# DSS_RCM register map
Vendor: Texas Instruments
Peripheral module from a debugger description file (folder awr2544).
Registers are 32-bit, read-write, no defined reset value unless marked. A register's access mark holds for its fields unless they carry their own. Offsets are as the file gives them; lines under a group give offsets from that group; [hi:lo] are bit positions; {n}, {i} and the like mark numbered series; 'fields as' and 'values as' point back to an identical list; <NAME> marks a mode.

## DSS_RCM
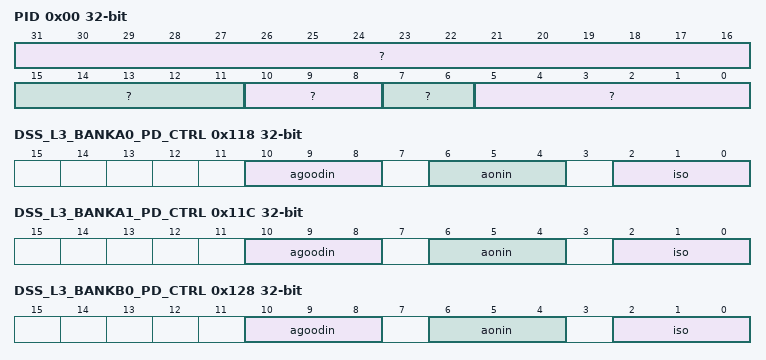
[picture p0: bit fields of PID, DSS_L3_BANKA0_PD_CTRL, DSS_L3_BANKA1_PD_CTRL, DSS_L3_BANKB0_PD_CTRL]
0x00 PID ro
  [31:16] ?, [15:11] ?, [10:8] ?, [7:6] ?, [5:0] ?
0x04 HW_REG0
  [31:0] hwreg — HW Reserved regiser
0x08 HW_REG1
  [31:0] hwreg — HW Reserved regiser
0x0C PREVIOUS_NAME
  [31:0] hwreg — HW Reserved regiser
0x10 HW_REG3
  [31:0] hwreg — HW Reserved regiser
0x90 DSS_HWA_CLK_SRC_SEL
  [2:0] clksrcsel — Select line for selecting source clock for DSS HWA. Data should be loaded as multibit. Write 3'b000 : TOPRCM_CR5_CLK Write 3'b111 : TOPRCM_SYS_CLK
0xBC DSS_HWA_CLK_GATE
  [2:0] gated — Clock gatring config for DSS HWA Data should be loaded as multibit. Write 3'b000 : Clock is ungated Write 3'b111 : Clock is gated
0xD0 DSS_CBUFF_CLK_GATE
  [2:0] gated — Clock gating config for DSS CBUFF Data should be loaded as multibit. Write 3'b000 : Clock is ungated Write 3'b111 : Clock is gated
0xD8 DSS_HWA_CLK_STATUS ro
  [1:0] clkinuse — Status shows the source clock slected for DSS HWA Clock
0x10C DSS_MCRC_RST_CTRL
  [2:0] assert — This feature is for debug purpose only. Software needs to ensure the state of Device/IP before configuring. Writing 3'b11 will assert reset for DSS MCRC
0x118 DSS_L3_BANKA0_PD_CTRL
  [10:8] agoodin — SW Control for <IP>_PD_CTRL Memory Array Power up CRTL1
  [6:4] aonin — SW Control for <IP>_PD_CTRL Memory Array Power up CRTL0
  [2:0] iso — SW Control for <IP>_PD_CTRL Isolation
0x11C DSS_L3_BANKA1_PD_CTRL
  fields as DSS_L3_BANKA0_PD_CTRL
0x128 DSS_L3_BANKB0_PD_CTRL
  fields as DSS_L3_BANKA0_PD_CTRL
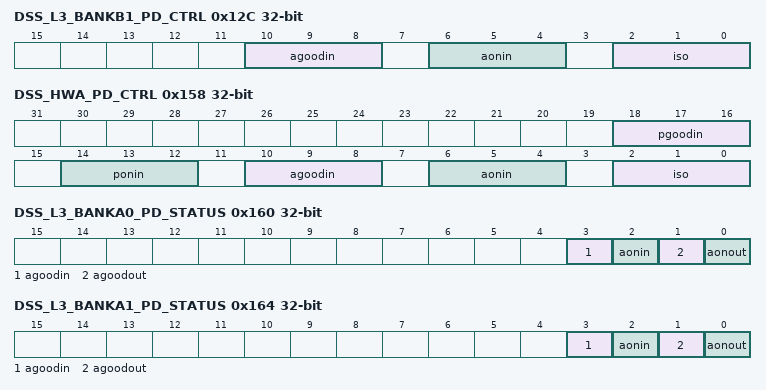
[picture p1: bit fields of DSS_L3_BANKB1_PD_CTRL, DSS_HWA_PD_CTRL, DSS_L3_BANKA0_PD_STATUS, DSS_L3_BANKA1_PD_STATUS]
0x12C DSS_L3_BANKB1_PD_CTRL
  fields as DSS_L3_BANKA0_PD_CTRL
0x158 DSS_HWA_PD_CTRL
  [18:16] pgoodin — SW Control for <IP>_PD_CTRL Power up CRTL1
  [14:12] ponin — SW Control for <IP>_PD_CTRL Power up CRTL0
  [10:8] agoodin — SW Control for <IP>_PD_CTRL Memory Array Power up CRTL1
  [6:4] aonin — SW Control for <IP>_PD_CTRL Memory Array Power up CRTL0
  [2:0] iso — SW Control for <IP>_PD_CTRL Isolation
0x160 DSS_L3_BANKA0_PD_STATUS ro
  [3] agoodin — Status for sticky control <IP>_PD_CTRL Memory Array Power up CRTL1
  [2] aonin — Status for sticky control <IP>_PD_CTRL Memory Array Power up CRTL0
  [1] agoodout — Status for <IP>_PD_CTRL Memory Array Power up CRTL1
  [0] aonout — Status for <IP>_PD_CTRL Memory Array Power up CRTL0
0x164 DSS_L3_BANKA1_PD_STATUS ro
  fields as DSS_L3_BANKA0_PD_STATUS
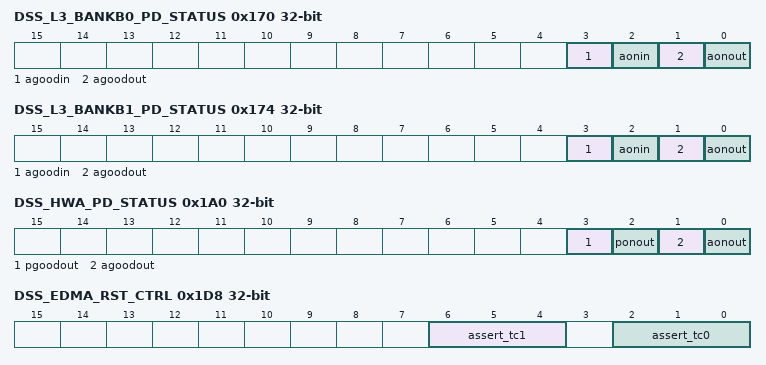
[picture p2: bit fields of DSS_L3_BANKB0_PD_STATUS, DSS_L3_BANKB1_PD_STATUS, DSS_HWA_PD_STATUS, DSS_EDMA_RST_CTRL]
0x170 DSS_L3_BANKB0_PD_STATUS ro
  fields as DSS_L3_BANKA0_PD_STATUS
0x174 DSS_L3_BANKB1_PD_STATUS ro
  fields as DSS_L3_BANKA0_PD_STATUS
0x1A0 DSS_HWA_PD_STATUS ro
  [3] pgoodout — Status for <IP>_PD_CTRL Power up CRTL1
  [2] ponout — Status for <IP>_PD_CTRL Power up CRTL0
  [1] agoodout — Status for <IP>_PD_CTRL Memory Array Power up CRTL1
  [0] aonout — Status for <IP>_PD_CTRL Memory Array Power up CRTL0
0x1B0 DSS_L3_PD_CTRL_STICKYBIT
  [2:0] set — Sticky bit for DSS L3 PD CTRL. Write 3'b111 to lock the configuration of DSS_L3_BANK*_PD_CTRL. Once this field is writen, there is no impact of changing the value of aonin and agoodin fields in DSS_L3_BANK*_PD_CTRL registers
0x1C8 DSS_HWA_RST_CTRL
  [2:0] assert — This register is for Debug Purposes only. Reset control for DSS HWA Data should be loaded as multibit. Write 3'b000: Reset is not asserted by SW. There could be another reset source which could reset the module. Refer to RCM spec for more details Write 3'b111 : Reset is asserted by SW
0x1CC DSS_HWA_RST_CTRL
  [2:0] assert — This register is for Debug Purposes only. Reset control for DSS TPCCA Data should be loaded as multibit. Write 3'b000: Reset is not asserted by SW. There could be another reset source which could reset the module. Refer to RCM spec for more details Write 3'b111 : Reset is asserted by SW
0x1D8 DSS_EDMA_RST_CTRL
  [6:4] assert_tc1 — This register is for Debug Purposes only. Reset control for DSS TPTCA1 Data should be loaded as multibit. Write 3'b000: Reset is not asserted by SW. There could be another reset source which could reset the module. Refer to RCM spec for more details Write 3'b111 : Reset is asserted by SW
  [2:0] assert_tc0 — This register is for Debug Purposes only. Reset control for DSS TPTCA0 Data should be loaded as multibit. Write 3'b000: Reset is not asserted by SW. There could be another reset source which could reset the module. Refer to RCM spec for more details Write 3'b111 : Reset is asserted by SW
0x1E4 DSS_CSI_CLK_GATE
  [2:0] gated — Clock gating config for DSS CSI2-TX Data should be loaded as multibit. Write 3'b000 : Clock is ungated Write 3'b111 : Clock is gated
0x1E8 DSS_IP_CLK_CFG
  [31:0] gate — IP clock gating configuration bits. Data should be loaded as multibit. Writing 3'b111 will gate the IP and disable the slave 2:0 - MCRC
{0xFD0+4i} HW_SPARE_RW{i} (i=0..3)
  [31:0] hw_spare_rw{i} — Reserved for HW R&D
{0xFE0+4i} HW_SPARE_RO{i} ro (i=0..3)
  [31:0] hw_spare_ro{i} — Reserved for HW R&D
0xFF0 HW_SPARE_WPH
  [31:0] hw_spare_wph — Reserved for HW R&D
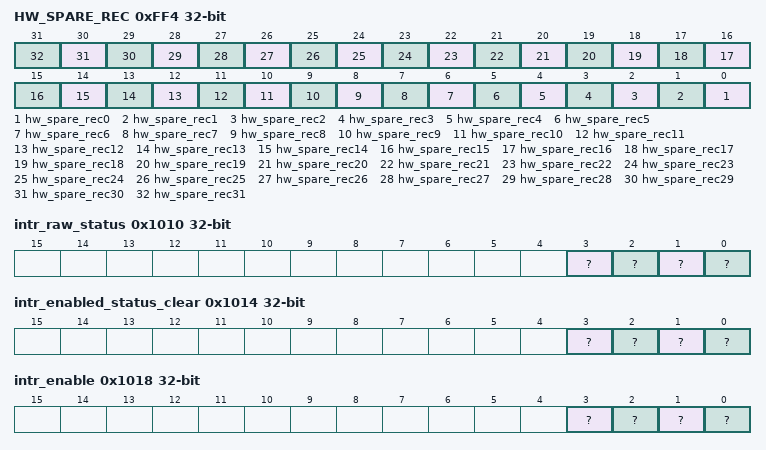
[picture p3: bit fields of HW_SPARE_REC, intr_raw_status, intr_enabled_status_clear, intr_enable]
0xFF4 HW_SPARE_REC
  [n] hw_spare_rec{n} (n=0..31) — Reserved for HW R&D
0x1008 LOCK0_KICK0 — - KICK0 component
  [31:0] ?
0x100C LOCK0_KICK1 — - KICK1 component
  [31:0] ?
0x1010 intr_raw_status — Interrupt Raw Status/Set Register
  [3] ? — Proxy0 access violation error. Raw status is read. Write a 1 to set the status. Writing a 0 has no effect.
  [2] ? — Kick access violation error. Raw status is read. Write a 1 to set the status. Writing a 0 has no effect.
  [1] ? — Addressing violation error. Raw status is read. Write a 1 to set the status. Writing a 0 has no effect.
  [0] ? — Protection violation error. Raw status is read. Write a 1 to set the status. Writing a 0 has no effect.
0x1014 intr_enabled_status_clear — Interrupt Enabled Status/Clear register
  [3] ? — Proxy0 access violation error. Enabled status is read. Write a 1 to clear the status. Writing a 0 has no effect.
  [2] ? — Kick access violation error. Enabled status is read. Write a 1 to clear the status. Writing a 0 has no effect.
  [1] ? — Addressing violation error. Enabled status is read. Write a 1 to clear the status. Writing a 0 has no effect.
  [0] ? — Protection violation error. Enabled status is read. Write a 1 to clear the status. Writing a 0 has no effect.
0x1018 intr_enable — Interrupt Enable register
  [3] ? — Proxy0 access violation error enable. Write a 1 to set the enable. Writing a 0 has no effect.
  [2] ? — Kick access violation error enable. Write a 1 to set the enable. Writing a 0 has no effect.
  [1] ? — Addressing violation error enable. Write a 1 to set the enable. Writing a 0 has no effect.
  [0] ? — Protection violation error enable. Write a 1 to set the enable. Writing a 0 has no effect.
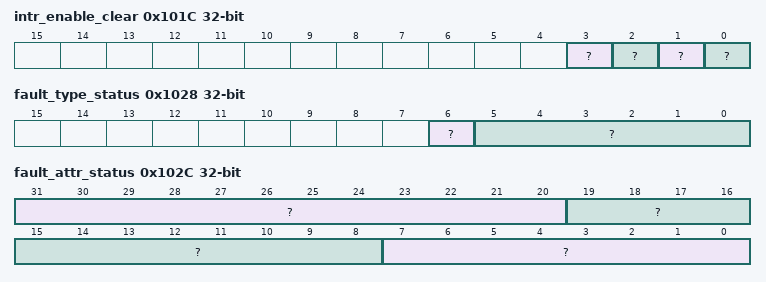
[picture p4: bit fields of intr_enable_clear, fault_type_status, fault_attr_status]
0x101C intr_enable_clear — Interrupt Enable Clear register
  [3] ? — Proxy0 access violation error enable clear. Write a 1 to clear the enable. Writing a 0 has no effect.
  [2] ? — Kick access violation error enable clear. Write a 1 to clear the enable. Writing a 0 has no effect.
  [1] ? — Addressing violation error enable clear. Write a 1 to clear the enable. Writing a 0 has no effect.
  [0] ? — Protection violation error enable clear. Write a 1 to clear the enable. Writing a 0 has no effect.
0x1020 eoi
  [7:0] ? — EOI vector value. Write this with interrupt distribution value in the chip.
0x1024 fault_address ro
  [31:0] ? — Fault Address.
0x1028 fault_type_status ro
  [6] ? — Non-secure access.
  [5:0] ? — Fault Type 10_0000 = Supervisor read fault - priv = 1 dir = 1 dtype != 1 01_0000 = Supervisor write fault - priv = 1 dir = 0 00_1000 = Supervisor execute fault - priv = 1 dir = 1 dtype = 1 00_0100 = User read fault - priv = 0 dir = 1 dtype = 1 00_0010 = User write fault - priv = 0 dir = 0 00_0001 = User execute fault - priv = 0 dir = 1 dtype = 1 00_0000 = No fault
0x102C fault_attr_status ro — Fault Attribute Status register
  [31:20] ? — XID.
  [19:8] ? — Route ID.
  [7:0] ? — Privilege ID.
0x1030 fault_clear wo
  [0] ? — Fault clear. Writing a 1 clears the current fault. Writing a 0 has no effect.
